AUTOSAR XML (schema 00046)
package /MyDataTypes
  base type myuint8: category=FIXED_LENGTH, base-type-size=8, base-type-encoding=NONE, native-declaration=unsigned char
  impl type myuint8: category=VALUE, base-type=myuint8, range phys 0..255, raw 0..255
package /Interfaces
  sender receiver interface IF_SR_DoorLockSens
    data DoorLock_State: type=myuint8, init-value=0
  client server interface IF_CS_LED
    operation LED_Switch: possible-error=[E_Ok, E_Not_Ok]
      arg LED_State: type=myuint8, direction=IN
    error E_Ok: error-code=0
    error E_Not_Ok: error-code=1
package /SWCs
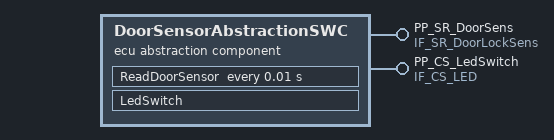
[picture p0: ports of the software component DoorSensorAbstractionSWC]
  ecu abstraction sw component type DoorSensorAbstractionSWC
    provide port PP_SR_DoorSens: provided-interface=IF_SR_DoorLockSens
    provide port PP_CS_LedSwitch: provided-interface=IF_CS_LED
    behavior IB_DoorLockAbstractionSWC
      timing event TE_10ms: start-on-event=ReadDoorSensor, period=0.01
      operation invoked event OIE_LedSwitch: start-on-event=LedSwitch, operation=PP_CS_LedSwitch.LED_Switch
      runnable ReadDoorSensor: symbol=ReadDoorSensor_Runnable
        data-write-access:
          access DA_DOORSTATE: accessed-variable=PP_SR_DoorSens.DoorLock_State
      runnable LedSwitch: symbol=LedSwitch_Runnable
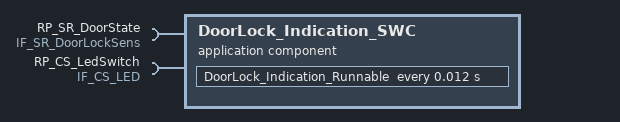
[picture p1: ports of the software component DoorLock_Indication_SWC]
  application sw component type DoorLock_Indication_SWC
    require port RP_SR_DoorState: required-interface=IF_SR_DoorLockSens
    require port RP_CS_LedSwitch: required-interface=IF_CS_LED
    behavior IB_DoorLock_Indication_SWC
      timing event TE_12ms: start-on-event=DoorLock_Indication_Runnable, period=0.012
      runnable DoorLock_Indication_Runnable
        data-read-access:
          access DA_Read: accessed-variable=RP_SR_DoorState.DoorLock_State
        sync call ServerCall: operation=RP_CS_LedSwitch.LED_Switch
package /Composition
  composition sw component type Composite_DoorLock_SWC
    component DoorLock_Abstraction_SWC: type=DoorSensorAbstractionSWC
    component DoorLockIndicationSWC: type=DoorLock_Indication_SWC
    connect DoorLock_Abstraction_SWC.PP_SR_DoorSens -> DoorLockIndicationSWC.RP_SR_DoorState
    connect DoorLock_Abstraction_SWC.PP_CS_LedSwitch -> DoorLockIndicationSWC.RP_CS_LedSwitch
